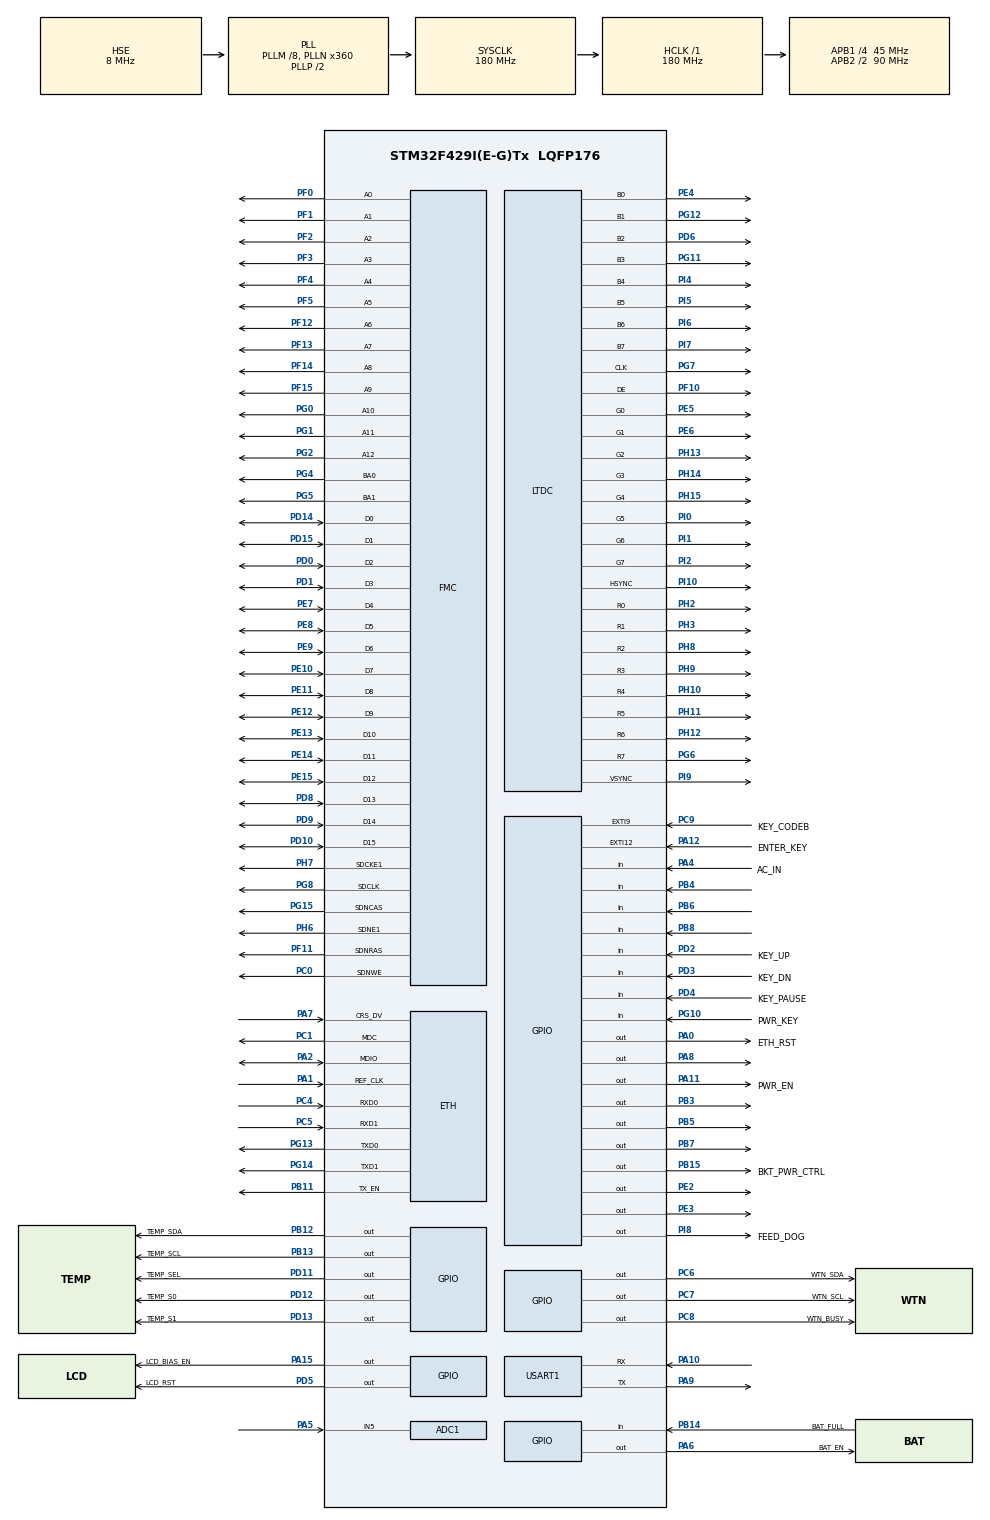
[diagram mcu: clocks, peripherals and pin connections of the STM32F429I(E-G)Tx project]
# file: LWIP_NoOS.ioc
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ADC1.Channel-0\#ChannelRegularConversion=ADC_CHANNEL_5
ADC1.NbrOfConversionFlag=1
ADC1.Rank-0\#ChannelRegularConversion=1
ADC1.SamplingTime-0\#ChannelRegularConversion=ADC_SAMPLETIME_3CYCLES
ADC1.master=1
ETH.MediaInterface=ETH_MEDIA_INTERFACE_RMII
ETH.PHY_Name_RMII=userPHY
ETH.PhyAddress=0
LWIP.GATEWAY_ADDRESS=192.168.001.001
LWIP.IP_ADDRESS=192.168.001.188
LWIP.LWIP_DHCP=1
LWIP.NETMASK_ADDRESS=255.255.255.000
LWIP.Version=v2.1.2_Cube
Mcu.Family=STM32F4
Mcu.Name=STM32F429I(E-G)Tx
Mcu.Package=LQFP176
NVIC.PriorityGroup=NVIC_PRIORITYGROUP_4
PA0/WKUP.GPIO_Label=ETH_RST
PA0/WKUP.Signal=GPIO_Output
PA1.Mode=RMII
PA1.Signal=ETH_REF_CLK
PA10.Mode=Asynchronous
PA10.Signal=USART1_RX
PA11.GPIO_Label=PWR_EN
PA11.PinState=GPIO_PIN_SET
PA11.Signal=GPIO_Output
PA12.GPIO_Label=ENTER_KEY
PA12.Signal=GPXTI12
PA13.Mode=Serial_Wire
PA13.Signal=SYS_JTMS-SWDIO
PA14.Mode=Serial_Wire
PA14.Signal=SYS_JTCK-SWCLK
PA15.GPIO_Label=LCD_BIAS_EN
PA15.Signal=GPIO_Output
PA2.Mode=RMII
PA2.Signal=ETH_MDIO
PA4.GPIO_Label=AC_IN
PA4.Signal=GPIO_Input
PA5.Signal=ADCx_IN5
PA6.GPIO_Label=BAT_EN
PA6.Signal=GPIO_Output
PA7.Mode=RMII
PA7.Signal=ETH_CRS_DV
PA8.Signal=GPIO_Output
PA9.Mode=Asynchronous
PA9.Signal=USART1_TX
PB11.Mode=RMII
PB11.Signal=ETH_TX_EN
PB12.GPIO_Label=TEMP_SDA
PB12.Signal=GPIO_Output
PB13.GPIO_Label=TEMP_SCL
PB13.Signal=GPIO_Output
PB14.GPIO_Label=BAT_FULL
PB14.Signal=GPIO_Input
PB15.GPIO_Label=BKT_PWR_CTRL
PB15.Signal=GPIO_Output
PB3.Signal=GPIO_Output
PB4.Signal=GPIO_Input
PB5.Signal=GPIO_Output
PB6.Signal=GPIO_Input
PB7.Signal=GPIO_Output
PB8.Signal=GPIO_Input
PB9.Signal=S_TIM4_CH4
PC0.Signal=FMC_SDNWE
PC1.Mode=RMII
PC1.Signal=ETH_MDC
PC10.Signal=USART3_TX
PC11.Signal=USART3_RX
PC14/OSC32_IN.Mode=LSE-External-Oscillator
PC14/OSC32_IN.Signal=RCC_OSC32_IN
PC15/OSC32_OUT.Mode=LSE-External-Oscillator
PC15/OSC32_OUT.Signal=RCC_OSC32_OUT
PC4.Mode=RMII
PC4.Signal=ETH_RXD0
PC5.Mode=RMII
PC5.Signal=ETH_RXD1
PC6.GPIO_Label=WTN_SDA
PC6.Signal=GPIO_Output
PC7.GPIO_Label=WTN_SCL
PC7.Signal=GPIO_Output
PC8.GPIO_Label=WTN_BUSY
PC8.Signal=GPIO_Output
PC9.GPIO_Label=KEY_CODEB
PC9.Signal=GPXTI9
PD0.Signal=FMC_D2_DA2
PD1.Signal=FMC_D3_DA3
PD10.Signal=FMC_D15_DA15
PD11.GPIO_Label=TEMP_SEL
PD11.Signal=GPIO_Output
PD12.GPIO_Label=TEMP_S0
PD12.Signal=GPIO_Output
PD13.GPIO_Label=TEMP_S1
PD13.Signal=GPIO_Output
PD14.Signal=FMC_D0_DA0
PD15.Signal=FMC_D1_DA1
PD2.GPIO_Label=KEY_UP
PD2.Signal=GPIO_Input
PD3.GPIO_Label=KEY_DN
PD3.Signal=GPIO_Input
PD4.GPIO_Label=KEY_PAUSE
PD4.Signal=GPIO_Input
PD5.GPIO_Label=LCD_RST
PD5.Signal=GPIO_Output
PD6.Mode=RGB888
PD6.Signal=LTDC_B2
PD8.Signal=FMC_D13_DA13
PD9.Signal=FMC_D14_DA14
PE0.Signal=FMC_NBL0
PE1.Signal=FMC_NBL1
PE10.Signal=FMC_D7_DA7
PE11.Signal=FMC_D8_DA8
PE12.Signal=FMC_D9_DA9
PE13.Signal=FMC_D10_DA10
PE14.Signal=FMC_D11_DA11
PE15.Signal=FMC_D12_DA12
PE2.Signal=GPIO_Output
PE3.Signal=GPIO_Output
PE4.Mode=RGB888
PE4.Signal=LTDC_B0
PE5.Mode=RGB888
PE5.Signal=LTDC_G0
PE6.Mode=RGB888
PE6.Signal=LTDC_G1
PE7.Signal=FMC_D4_DA4
PE8.Signal=FMC_D5_DA5
PE9.Signal=FMC_D6_DA6
PF0.Signal=FMC_A0
PF1.Signal=FMC_A1
PF10.Mode=RGB888
PF10.Signal=LTDC_DE
PF11.Signal=FMC_SDNRAS
PF12.Signal=FMC_A6
PF13.Signal=FMC_A7
PF14.Signal=FMC_A8
PF15.Signal=FMC_A9
PF2.Signal=FMC_A2
PF3.Signal=FMC_A3
PF4.Signal=FMC_A4
PF5.Signal=FMC_A5
PF6.Signal=SPI5_NSS
PF7.Signal=SPI5_SCK
PF8.Signal=SPI5_MISO
PF9.Signal=SPI5_MOSI
PG0.Signal=FMC_A10
PG1.Signal=FMC_A11
PG10.GPIO_Label=PWR_KEY
PG10.Signal=GPIO_Input
PG11.Mode=RGB888
PG11.Signal=LTDC_B3
PG12.Mode=RGB888
PG12.Signal=LTDC_B1
PG13.Mode=RMII
PG13.Signal=ETH_TXD0
PG14.Mode=RMII
PG14.Signal=ETH_TXD1
PG15.Signal=FMC_SDNCAS
PG2.Signal=FMC_A12
PG4.Signal=FMC_A14_BA0
PG5.Signal=FMC_A15_BA1
PG6.Mode=RGB888
PG6.Signal=LTDC_R7
PG7.Mode=RGB888
PG7.Signal=LTDC_CLK
PG8.Signal=FMC_SDCLK
PH0/OSC_IN.Mode=HSE-External-Oscillator
PH0/OSC_IN.Signal=RCC_OSC_IN
PH1/OSC_OUT.Mode=HSE-External-Oscillator
PH1/OSC_OUT.Signal=RCC_OSC_OUT
PH10.Mode=RGB888
PH10.Signal=LTDC_R4
PH11.Mode=RGB888
PH11.Signal=LTDC_R5
PH12.Mode=RGB888
PH12.Signal=LTDC_R6
PH13.Mode=RGB888
PH13.Signal=LTDC_G2
PH14.Mode=RGB888
PH14.Signal=LTDC_G3
PH15.Mode=RGB888
PH15.Signal=LTDC_G4
PH2.Mode=RGB888
PH2.Signal=LTDC_R0
PH3.Mode=RGB888
PH3.Signal=LTDC_R1
PH6.Mode=SdramChipSelect2_1
PH6.Signal=FMC_SDNE1
PH7.Mode=SdramChipSelect2_1
PH7.Signal=FMC_SDCKE1
PH8.Mode=RGB888
PH8.Signal=LTDC_R2
PH9.Mode=RGB888
PH9.Signal=LTDC_R3
PI0.Mode=RGB888
PI0.Signal=LTDC_G5
PI1.Mode=RGB888
PI1.Signal=LTDC_G6
PI10.Mode=RGB888
PI10.Signal=LTDC_HSYNC
PI2.Mode=RGB888
PI2.Signal=LTDC_G7
PI4.Mode=RGB888
PI4.Signal=LTDC_B4
PI5.Mode=RGB888
PI5.Signal=LTDC_B5
PI6.Mode=RGB888
PI6.Signal=LTDC_B6
PI7.Mode=RGB888
PI7.Signal=LTDC_B7
PI8.GPIO_Label=FEED_DOG
PI8.GPIO_ModeDefaultOutputPP=GPIO_MODE_OUTPUT_OD
PI8.PinState=GPIO_PIN_SET
PI8.Signal=GPIO_Output
PI9.Mode=RGB888
PI9.Signal=LTDC_VSYNC
ProjectManager.HeapSize=0x200
ProjectManager.StackSize=0x400
ProjectManager.TargetToolchain=MDK-ARM V5.27
RCC.48MHZClocksFreq_Value=90000000
RCC.AHBFreq_Value=180000000
RCC.APB1CLKDivider=RCC_HCLK_DIV4
RCC.APB1Freq_Value=45000000
RCC.APB1TimFreq_Value=90000000
RCC.APB2CLKDivider=RCC_HCLK_DIV2
RCC.APB2Freq_Value=90000000
RCC.APB2TimFreq_Value=180000000
RCC.CortexFreq_Value=180000000
RCC.HCLKFreq_Value=180000000
RCC.HSE_VALUE=8000000
RCC.HSI_VALUE=16000000
RCC.PLLM=8
RCC.PLLN=360
RCC.PLLSAIN=100
RCC.PLLSourceVirtual=RCC_PLLSOURCE_HSE
RCC.RCC_RTC_Clock_Source=RCC_RTCCLKSOURCE_LSE
RCC.RCC_RTC_Clock_SourceVirtual=RCC_RTCCLKSOURCE_LSE
RCC.SYSCLKFreq_VALUE=180000000
RCC.SYSCLKSource=RCC_SYSCLKSOURCE_PLLCLK
RCC.VCOOutputFreq_Value=360000000
SH.ADCx_IN5.0=ADC1_IN5,IN5
SH.FMC_A0.0=FMC_A0,13b-sda1
SH.FMC_A1.0=FMC_A1,13b-sda1
SH.FMC_A10.0=FMC_A10,13b-sda1
SH.FMC_A11.0=FMC_A11,13b-sda1
SH.FMC_A12.0=FMC_A12,13b-sda1
SH.FMC_A14_BA0.0=FMC_BA0,FourSdramBanks1
SH.FMC_A15_BA1.0=FMC_BA1,FourSdramBanks1
SH.FMC_A2.0=FMC_A2,13b-sda1
SH.FMC_A3.0=FMC_A3,13b-sda1
SH.FMC_A4.0=FMC_A4,13b-sda1
SH.FMC_A5.0=FMC_A5,13b-sda1
SH.FMC_A6.0=FMC_A6,13b-sda1
SH.FMC_A7.0=FMC_A7,13b-sda1
SH.FMC_A8.0=FMC_A8,13b-sda1
SH.FMC_A9.0=FMC_A9,13b-sda1
SH.FMC_D0_DA0.0=FMC_D0,sd-16b-d1
SH.FMC_D10_DA10.0=FMC_D10,sd-16b-d1
SH.FMC_D11_DA11.0=FMC_D11,sd-16b-d1
SH.FMC_D12_DA12.0=FMC_D12,sd-16b-d1
SH.FMC_D13_DA13.0=FMC_D13,sd-16b-d1
SH.FMC_D14_DA14.0=FMC_D14,sd-16b-d1
SH.FMC_D15_DA15.0=FMC_D15,sd-16b-d1
SH.FMC_D1_DA1.0=FMC_D1,sd-16b-d1
SH.FMC_D2_DA2.0=FMC_D2,sd-16b-d1
SH.FMC_D3_DA3.0=FMC_D3,sd-16b-d1
SH.FMC_D4_DA4.0=FMC_D4,sd-16b-d1
SH.FMC_D5_DA5.0=FMC_D5,sd-16b-d1
SH.FMC_D6_DA6.0=FMC_D6,sd-16b-d1
SH.FMC_D7_DA7.0=FMC_D7,sd-16b-d1
SH.FMC_D8_DA8.0=FMC_D8,sd-16b-d1
SH.FMC_D9_DA9.0=FMC_D9,sd-16b-d1
SH.FMC_NBL0.0=FMC_NBL0
SH.FMC_NBL1.0=FMC_NBL1
SH.FMC_SDCLK.0=FMC_SDCLK,13b-sda1
SH.FMC_SDNCAS.0=FMC_SDNCAS,13b-sda1
SH.FMC_SDNRAS.0=FMC_SDNRAS,13b-sda1
SH.FMC_SDNWE.0=FMC_SDNWE,13b-sda1
SH.S_TIM4_CH4.0=TIM4_CH4
USART1.VirtualMode=VM_ASYNC
USART1.WordLength=WORDLENGTH_8B
VP_LWIP_VS_Enabled.Mode=Enabled
VP_RTC_VS_RTC_Activate.Mode=RTC_Enabled
board=custom

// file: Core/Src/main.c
/* USER CODE BEGIN Header */
/**
  ******************************************************************************
  * @file           : main.c
  * @brief          : Main program body
  ******************************************************************************
  * @attention
  *
  * <h2><center>&copy; Copyright (c) 2020 STMicroelectronics.
  * All rights reserved.</center></h2>
  *
  * This software component is licensed by ST under BSD 3-Clause license,
  * the "License"; You may not use this file except in compliance with the
  * License. You may obtain a copy of the License at:
  *                        opensource.org/licenses/BSD-3-Clause
  *
  ******************************************************************************
  */
/* USER CODE END Header */
#include "main.h"
#include "adc.h"
#include "ltdc.h"
#include "lwip.h"
#include "rtc.h"
#include "usart.h"
#include "gpio.h"
#include "fmc.h"

/* USER CODE BEGIN Includes */
#include <stdio.h>
/* USER CODE END Includes */

void SystemClock_Config(void);

int main(void)
{

  /* MCU Configuration--------------------------------------------------------*/

  /* Reset of all peripherals, Initializes the Flash interface and the Systick. */
  HAL_Init();

  /* Configure the system clock */
  SystemClock_Config();

  /* USER CODE BEGIN SysInit */
  MX_GPIO_Init();
  HAL_GPIO_WritePin(GPIOG, PWR_KEY_Pin, GPIO_PIN_SET);
  HAL_GPIO_WritePin(GPIOA, ETH_RST_Pin, GPIO_PIN_RESET);
  HAL_Delay(100);
  HAL_GPIO_WritePin(GPIOA, ETH_RST_Pin, GPIO_PIN_SET);
  HAL_Delay(100);
  /* USER CODE END SysInit */

  /* Initialize all configured peripherals */

  MX_RTC_Init();
  MX_ADC1_Init();
  MX_FMC_Init();
  MX_LTDC_Init();
  MX_USART1_UART_Init();
  MX_LWIP_Init();

  /* Infinite loop */
  /* USER CODE BEGIN WHILE */
  while (1)
  {
    MX_LWIP_Process();
    printf("Hello World\r\n");
    /* USER CODE END WHILE */

  }
}

void SystemClock_Config(void)
{
  RCC_OscInitTypeDef RCC_OscInitStruct = {0};
  RCC_ClkInitTypeDef RCC_ClkInitStruct = {0};
  RCC_PeriphCLKInitTypeDef PeriphClkInitStruct = {0};

  /** Configure the main internal regulator output voltage
  */
  __HAL_RCC_PWR_CLK_ENABLE();
  __HAL_PWR_VOLTAGESCALING_CONFIG(PWR_REGULATOR_VOLTAGE_SCALE1);
  /** Initializes the RCC Oscillators according to the specified parameters
  * in the RCC_OscInitTypeDef structure.
  */
  RCC_OscInitStruct.OscillatorType = RCC_OSCILLATORTYPE_HSE|RCC_OSCILLATORTYPE_LSE;
  RCC_OscInitStruct.HSEState = RCC_HSE_ON;
  RCC_OscInitStruct.LSEState = RCC_LSE_ON;
  RCC_OscInitStruct.PLL.PLLState = RCC_PLL_ON;
  RCC_OscInitStruct.PLL.PLLSource = RCC_PLLSOURCE_HSE;
  RCC_OscInitStruct.PLL.PLLM = 8;
  RCC_OscInitStruct.PLL.PLLN = 360;
  RCC_OscInitStruct.PLL.PLLP = RCC_PLLP_DIV2;
  RCC_OscInitStruct.PLL.PLLQ = 4;
  if (HAL_RCC_OscConfig(&RCC_OscInitStruct) != HAL_OK)
  {
    Error_Handler();
  }
  /** Activate the Over-Drive mode
  */
  if (HAL_PWREx_EnableOverDrive() != HAL_OK)
  {
    Error_Handler();
  }
  /** Initializes the CPU, AHB and APB buses clocks
  */
  RCC_ClkInitStruct.ClockType = RCC_CLOCKTYPE_HCLK|RCC_CLOCKTYPE_SYSCLK
                              |RCC_CLOCKTYPE_PCLK1|RCC_CLOCKTYPE_PCLK2;
  RCC_ClkInitStruct.SYSCLKSource = RCC_SYSCLKSOURCE_PLLCLK;
  RCC_ClkInitStruct.AHBCLKDivider = RCC_SYSCLK_DIV1;
  RCC_ClkInitStruct.APB1CLKDivider = RCC_HCLK_DIV4;
  RCC_ClkInitStruct.APB2CLKDivider = RCC_HCLK_DIV2;

  if (HAL_RCC_ClockConfig(&RCC_ClkInitStruct, FLASH_LATENCY_5) != HAL_OK)
  {
    Error_Handler();
  }
  PeriphClkInitStruct.PeriphClockSelection = RCC_PERIPHCLK_LTDC|RCC_PERIPHCLK_RTC;
  PeriphClkInitStruct.PLLSAI.PLLSAIN = 100;
  PeriphClkInitStruct.PLLSAI.PLLSAIR = 2;
  PeriphClkInitStruct.PLLSAIDivR = RCC_PLLSAIDIVR_2;
  PeriphClkInitStruct.RTCClockSelection = RCC_RTCCLKSOURCE_LSE;
  if (HAL_RCCEx_PeriphCLKConfig(&PeriphClkInitStruct) != HAL_OK)
  {
    Error_Handler();
  }
}

void Error_Handler(void)
{
}

/************************ (C) COPYRIGHT STMicroelectronics *****END OF FILE****/
